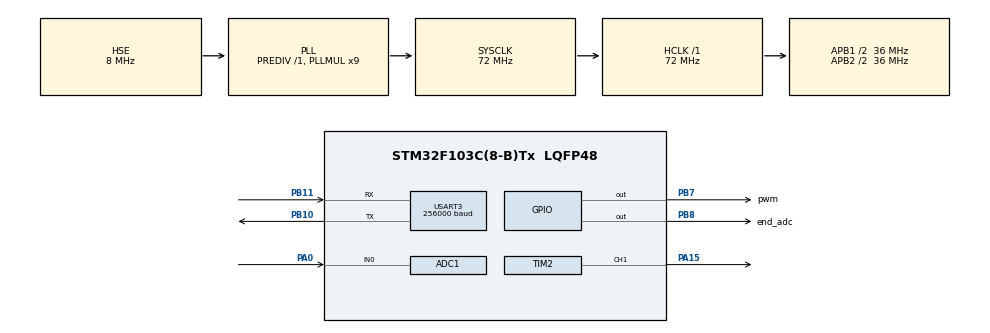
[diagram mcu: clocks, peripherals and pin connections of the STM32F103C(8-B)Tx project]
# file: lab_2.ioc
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ADC1.Channel-0\#ChannelRegularConversion=ADC_CHANNEL_0
ADC1.NbrOfConversion=1
ADC1.NbrOfConversionFlag=1
ADC1.Rank-0\#ChannelRegularConversion=1
ADC1.SamplingTime-0\#ChannelRegularConversion=ADC_SAMPLETIME_7CYCLES_5
ADC1.master=1
Mcu.Family=STM32F1
Mcu.Name=STM32F103C(8-B)Tx
Mcu.Package=LQFP48
NVIC.ADC1_2_IRQn=true\:0\:0\:false\:false\:true\:true\:true
NVIC.PriorityGroup=NVIC_PRIORITYGROUP_4
NVIC.TIM2_IRQn=true\:0\:0\:false\:false\:true\:true\:true
PA0-WKUP.Signal=ADCx_IN0
PA13.Mode=Serial_Wire
PA13.Signal=SYS_JTMS-SWDIO
PA14.Mode=Serial_Wire
PA14.Signal=SYS_JTCK-SWCLK
PA15.Signal=S_TIM2_CH1_ETR
PB10.Mode=Asynchronous
PB10.Signal=USART3_TX
PB11.Mode=Asynchronous
PB11.Signal=USART3_RX
PB7.GPIO_Label=pwm
PB7.Signal=GPIO_Output
PB8.GPIO_Label=end_adc
PB8.Signal=GPIO_Output
PD0-OSC_IN.Mode=HSE-External-Oscillator
PD0-OSC_IN.Signal=RCC_OSC_IN
PD1-OSC_OUT.Mode=HSE-External-Oscillator
PD1-OSC_OUT.Signal=RCC_OSC_OUT
ProjectManager.HeapSize=0x200
ProjectManager.StackSize=0x400
ProjectManager.TargetToolchain=STM32CubeIDE
RCC.ADCPresc=RCC_ADCPCLK2_DIV8
RCC.AHBFreq_Value=72000000
RCC.APB1CLKDivider=RCC_HCLK_DIV2
RCC.APB1Freq_Value=36000000
RCC.APB1TimFreq_Value=72000000
RCC.APB2CLKDivider=RCC_HCLK_DIV2
RCC.APB2Freq_Value=36000000
RCC.APB2TimFreq_Value=72000000
RCC.HCLKFreq_Value=72000000
RCC.PLLMUL=RCC_PLL_MUL9
RCC.PLLSourceVirtual=RCC_PLLSOURCE_HSE
RCC.SYSCLKFreq_VALUE=72000000
RCC.SYSCLKSource=RCC_SYSCLKSOURCE_PLLCLK
RCC.USBFreq_Value=72000000
SH.ADCx_IN0.0=ADC1_IN0,IN0
SH.S_TIM2_CH1_ETR.0=TIM2_CH1,Output Compare1 CH1
TIM2.AutoReloadPreload=TIM_AUTORELOAD_PRELOAD_DISABLE
TIM2.Channel-Output\ Compare1\ CH1=TIM_CHANNEL_1
TIM2.OCPolarity_1=TIM_OCPOLARITY_HIGH
TIM2.Period=124
TIM2.Prescaler=71
TIM2.TIM_MasterOutputTrigger=TIM_TRGO_OC1REF
USART3.BaudRate=256000
USART3.VirtualMode=VM_ASYNC
VP_TIM2_VS_ClockSourceINT.Mode=Internal
board=custom

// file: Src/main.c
/* USER CODE BEGIN Header */
/**
  ******************************************************************************
  * @file           : main.c
  * @brief          : Main program body
  ******************************************************************************
  * @attention
  *
  * <h2><center>&copy; Copyright (c) 2020 STMicroelectronics.
  * All rights reserved.</center></h2>
  *
  * This software component is licensed by ST under BSD 3-Clause license,
  * the "License"; You may not use this file except in compliance with the
  * License. You may obtain a copy of the License at:
  *                        opensource.org/licenses/BSD-3-Clause
  *
  ******************************************************************************
  */
/* USER CODE END Header */

#include "main.h"

/* USER CODE BEGIN PD */
#define MAX_CONVERSIONS 4
#define MAX_PWM 123
/* USER CODE END PD */

ADC_HandleTypeDef hadc1;

TIM_HandleTypeDef htim2;

UART_HandleTypeDef huart3;

/* USER CODE BEGIN PV */
volatile uint32_t PWM_val = 60;
volatile uint32_t adc_debug = 0;
volatile uint8_t current_conversion = 0;
volatile uint32_t adc_values[4] = {0};
/* USER CODE END PV */

void SystemClock_Config(void);
static void MX_GPIO_Init(void);
static void MX_ADC1_Init(void);
static void MX_TIM2_Init(void);
static void MX_USART3_UART_Init(void);

int main(void)
{

  /* MCU Configuration--------------------------------------------------------*/

  /* Reset of all peripherals, Initializes the Flash interface and the Systick. */
  HAL_Init();

  /* Configure the system clock */
  SystemClock_Config();

  /* Initialize all configured peripherals */
  MX_GPIO_Init();
  MX_ADC1_Init();
  MX_TIM2_Init();
  MX_USART3_UART_Init();
  /* USER CODE BEGIN 2 */

  //htim2.Instance->DIER |= TIM_DIER_CC1IE;
  __HAL_TIM_ENABLE_IT(&htim2, TIM_IT_CC1);
  __HAL_TIM_CLEAR_IT(&htim2, TIM_IT_CC1);

  __HAL_TIM_ENABLE_IT(&htim2, TIM_IT_UPDATE );
  HAL_TIM_Base_Start_IT(&htim2);

  __HAL_TIM_SET_COMPARE(&htim2, TIM_IT_UPDATE, PWM_val);
  HAL_ADC_Start_IT(&hadc1);
  /* USER CODE END 2 */

  /* Infinite loop */
  while (1)
  {

  }
}

void SystemClock_Config(void)
{
  RCC_OscInitTypeDef RCC_OscInitStruct = {0};
  RCC_ClkInitTypeDef RCC_ClkInitStruct = {0};
  RCC_PeriphCLKInitTypeDef PeriphClkInit = {0};

  /** Initializes the CPU, AHB and APB busses clocks
  */
  RCC_OscInitStruct.OscillatorType = RCC_OSCILLATORTYPE_HSE;
  RCC_OscInitStruct.HSEState = RCC_HSE_ON;
  RCC_OscInitStruct.HSEPredivValue = RCC_HSE_PREDIV_DIV1;
  RCC_OscInitStruct.HSIState = RCC_HSI_ON;
  RCC_OscInitStruct.PLL.PLLState = RCC_PLL_ON;
  RCC_OscInitStruct.PLL.PLLSource = RCC_PLLSOURCE_HSE;
  RCC_OscInitStruct.PLL.PLLMUL = RCC_PLL_MUL9;
  if (HAL_RCC_OscConfig(&RCC_OscInitStruct) != HAL_OK)
  {
    Error_Handler();
  }
  /** Initializes the CPU, AHB and APB busses clocks
  */
  RCC_ClkInitStruct.ClockType = RCC_CLOCKTYPE_HCLK|RCC_CLOCKTYPE_SYSCLK
                              |RCC_CLOCKTYPE_PCLK1|RCC_CLOCKTYPE_PCLK2;
  RCC_ClkInitStruct.SYSCLKSource = RCC_SYSCLKSOURCE_PLLCLK;
  RCC_ClkInitStruct.AHBCLKDivider = RCC_SYSCLK_DIV1;
  RCC_ClkInitStruct.APB1CLKDivider = RCC_HCLK_DIV2;
  RCC_ClkInitStruct.APB2CLKDivider = RCC_HCLK_DIV2;

  if (HAL_RCC_ClockConfig(&RCC_ClkInitStruct, FLASH_LATENCY_2) != HAL_OK)
  {
    Error_Handler();
  }
  PeriphClkInit.PeriphClockSelection = RCC_PERIPHCLK_ADC;
  PeriphClkInit.AdcClockSelection = RCC_ADCPCLK2_DIV8;
  if (HAL_RCCEx_PeriphCLKConfig(&PeriphClkInit) != HAL_OK)
  {
    Error_Handler();
  }
}

static void MX_ADC1_Init(void)
{

  ADC_ChannelConfTypeDef sConfig = {0};

  /** Common config
  */
  hadc1.Instance = ADC1;
  hadc1.Init.ScanConvMode = ADC_SCAN_DISABLE;
  hadc1.Init.ContinuousConvMode = DISABLE;
  hadc1.Init.DiscontinuousConvMode = DISABLE;
  hadc1.Init.ExternalTrigConv = ADC_SOFTWARE_START;
  hadc1.Init.DataAlign = ADC_DATAALIGN_RIGHT;
  hadc1.Init.NbrOfConversion = 1;
  if (HAL_ADC_Init(&hadc1) != HAL_OK)
  {
    Error_Handler();
  }
  /** Configure Regular Channel
  */
  sConfig.Channel = ADC_CHANNEL_0;
  sConfig.Rank = ADC_REGULAR_RANK_1;
  sConfig.SamplingTime = ADC_SAMPLETIME_7CYCLES_5;
  if (HAL_ADC_ConfigChannel(&hadc1, &sConfig) != HAL_OK)
  {
    Error_Handler();
  }

}

static void MX_TIM2_Init(void)
{

  TIM_ClockConfigTypeDef sClockSourceConfig = {0};
  TIM_MasterConfigTypeDef sMasterConfig = {0};
  TIM_OC_InitTypeDef sConfigOC = {0};

  htim2.Instance = TIM2;
  htim2.Init.Prescaler = 71;
  htim2.Init.CounterMode = TIM_COUNTERMODE_UP;
  htim2.Init.Period = 124;
  htim2.Init.ClockDivision = TIM_CLOCKDIVISION_DIV1;
  htim2.Init.AutoReloadPreload = TIM_AUTORELOAD_PRELOAD_DISABLE;
  if (HAL_TIM_Base_Init(&htim2) != HAL_OK)
  {
    Error_Handler();
  }
  sClockSourceConfig.ClockSource = TIM_CLOCKSOURCE_INTERNAL;
  if (HAL_TIM_ConfigClockSource(&htim2, &sClockSourceConfig) != HAL_OK)
  {
    Error_Handler();
  }
  if (HAL_TIM_OC_Init(&htim2) != HAL_OK)
  {
    Error_Handler();
  }
  sMasterConfig.MasterOutputTrigger = TIM_TRGO_OC1REF;
  sMasterConfig.MasterSlaveMode = TIM_MASTERSLAVEMODE_DISABLE;
  if (HAL_TIMEx_MasterConfigSynchronization(&htim2, &sMasterConfig) != HAL_OK)
  {
    Error_Handler();
  }
  sConfigOC.OCMode = TIM_OCMODE_TIMING;
  sConfigOC.Pulse = 0;
  sConfigOC.OCPolarity = TIM_OCPOLARITY_HIGH;
  sConfigOC.OCFastMode = TIM_OCFAST_DISABLE;
  if (HAL_TIM_OC_ConfigChannel(&htim2, &sConfigOC, TIM_CHANNEL_1) != HAL_OK)
  {
    Error_Handler();
  }
  HAL_TIM_MspPostInit(&htim2);

}

static void MX_USART3_UART_Init(void)
{

  huart3.Instance = USART3;
  huart3.Init.BaudRate = 256000;
  huart3.Init.WordLength = UART_WORDLENGTH_8B;
  huart3.Init.StopBits = UART_STOPBITS_1;
  huart3.Init.Parity = UART_PARITY_NONE;
  huart3.Init.Mode = UART_MODE_TX_RX;
  huart3.Init.HwFlowCtl = UART_HWCONTROL_NONE;
  huart3.Init.OverSampling = UART_OVERSAMPLING_16;
  if (HAL_UART_Init(&huart3) != HAL_OK)
  {
    Error_Handler();
  }

}

static void MX_GPIO_Init(void)
{
  GPIO_InitTypeDef GPIO_InitStruct = {0};

  /* GPIO Ports Clock Enable */
  __HAL_RCC_GPIOD_CLK_ENABLE();
  __HAL_RCC_GPIOA_CLK_ENABLE();
  __HAL_RCC_GPIOB_CLK_ENABLE();

  /*Configure GPIO pin Output Level */
  HAL_GPIO_WritePin(GPIOB, pwm_Pin|end_adc_Pin, GPIO_PIN_RESET);

  /*Configure GPIO pins : pwm_Pin end_adc_Pin */
  GPIO_InitStruct.Pin = pwm_Pin|end_adc_Pin;
  GPIO_InitStruct.Mode = GPIO_MODE_OUTPUT_PP;
  GPIO_InitStruct.Pull = GPIO_NOPULL;
  GPIO_InitStruct.Speed = GPIO_SPEED_FREQ_LOW;
  HAL_GPIO_Init(GPIOB, &GPIO_InitStruct);

}

void Error_Handler(void)
{
}

/************************ (C) COPYRIGHT STMicroelectronics *****END OF FILE****/
